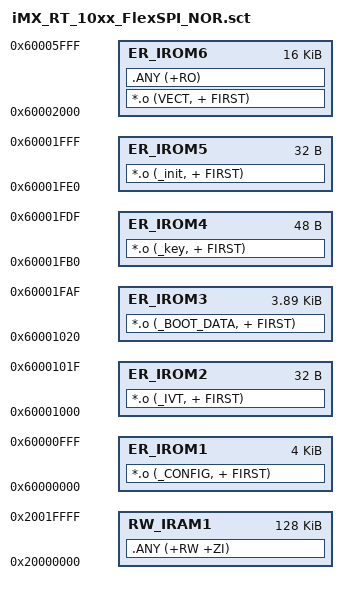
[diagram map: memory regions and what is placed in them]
;/* iMX_RT_10xx_FlexSPI_NOR.sct - for iMX RT 10xx running from FlexSPI NOR    */
;/* 256k RAM                                                                  */

LR_IROM1 0x60000000 0x00001000  {    ; load region size_region
  ER_IROM1 0x60000000 0x00001000  {  ; load address = execution address
   *.o (_CONFIG, + FIRST)
  }
  RW_IRAM1 0x20000000 0x00020000  {  ; RW data
   .ANY (+RW +ZI)
  }
}

LR_IROM2 0x60001000 0x00000020  {    ; load region size_region
  ER_IROM2 0x60001000 0x00000020  {  ; load address = execution address
   *.o (_IVT, + FIRST)
  }
}

LR_IROM3 0x60001020 0x00000f90  {    ; load region size_region
  ER_IROM3 0x60001020 0x00000f90  {  ; load address = execution address
   *.o (_BOOT_DATA, + FIRST)
  }
}

LR_IROM4 0x60001fb0 0x00000030  {    ; load region size_region
  ER_IROM4 0x60001fb0 0x00000030  {  ; load address = execution address
   *.o (_key, + FIRST)
  }
}

LR_IROM5 0x60001fe0 0x00000020  {    ; load region size_region
  ER_IROM5 0x60001fe0 0x00000020  {  ; load address = execution address
   *.o (_init, + FIRST)
  }
}

LR_IROM6 0x60002000 0x00004000  {    ; load region size_region
  ER_IROM6 0x60002000 0x00004000  {  ; load address = execution address
   *.o (VECT, + FIRST)
   .ANY (+RO)
  }
}


